# CC430F5123 register map
Registers are 16-bit, read-write, reset 0x0 unless marked. A register's access mark holds for its fields unless they carry their own. Offsets are from the block's base; [hi:lo] are bit positions; {n}, {i} and the like mark numbered series.

## USCI_B0_SPI_Mode
Base 0x00000000
0x5E0 UCB0CTLW0_SPI — USCI B0 Control Word Register 0
0x5E0 UCB0CTL1_SPI 8-bit — USCI B0 Control Register 1
  [8:7] UCSSEL — USCI 1 Clock Source Select 1
    {v}=USCI 0 Clock Source: {v} (v=0..3)
  [0] UCSWRST — USCI Software Reset
0x5E1 UCB0CTL0_SPI 8-bit — USCI B0 Control Register 0
  [7] UCCKPH — Sync. Mode: Clock Phase
  [6] UCCKPL — Sync. Mode: Clock Polarity
  [5] UCMSB — Sync. Mode: MSB first 0:LSB / 1:MSB
  [4] UC7BIT — Sync. Mode: Data Bits 0:8-bits / 1:7-bits
  [3] UCMST — Sync. Mode: Master Select
  [3:2] UCMODE — Sync. Mode: USCI Mode 1
    {v}=Sync. Mode: USCI Mode: {v} (v=0..3)
  [0] UCSYNC — Sync-Mode 0:UART-Mode / 1:SPI-Mode
0x5E6 UCB0BRW_SPI — USCI B0 Baud Word Rate 0
0x5E6 UCB0BR0_SPI 8-bit — USCI B0 Baud Rate 0
0x5E7 UCB0BR1_SPI 8-bit — USCI B0 Baud Rate 1
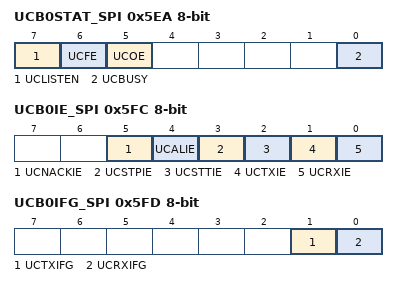
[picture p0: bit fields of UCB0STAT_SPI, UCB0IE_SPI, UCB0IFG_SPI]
0x5EA UCB0STAT_SPI 8-bit — USCI B0 Status Register
  [7] UCLISTEN — USCI Listen mode
  [6] UCFE — USCI Frame Error Flag
  [5] UCOE — USCI Overrun Error Flag
  [0] UCBUSY — USCI Busy Flag
0x5EC UCB0RXBUF_SPI 8-bit — USCI B0 Receive Buffer
0x5EE UCB0TXBUF_SPI 8-bit — USCI B0 Transmit Buffer
0x5FC UCB0ICTL_SPI — USCI B0 Interrupt Enable Register
0x5FC UCB0IE_SPI 8-bit — USCI B0 Interrupt Enable Register
  [5] UCNACKIE — NACK Condition interrupt enable
  [4] UCALIE — Arbitration Lost interrupt enable
  [3] UCSTPIE — STOP Condition interrupt enable
  [2] UCSTTIE — START Condition interrupt enable
  [1] UCTXIE — USCI Transmit Interrupt Enable
  [0] UCRXIE — USCI Receive Interrupt Enable
0x5FD UCB0IFG_SPI 8-bit — USCI B0 Interrupt Flags Register
  [1] UCTXIFG — USCI Transmit Interrupt Flag
  [0] UCRXIFG — USCI Receive Interrupt Flag
0x5FE UCB0IV_SPI — USCI B0 Interrupt Vector Register

## USCI_B0_I2C_Mode
Base 0x00000000
0x5E0 UCB0CTLW0 — USCI B0 Control Word Register 0
0x5E0 UCB0CTL1 8-bit — USCI B0 Control Register 1
  [8:7] UCSSEL — USCI 1 Clock Source Select 1
    {v}=USCI 0 Clock Source: {v} (v=0..3)
  [4] UCTR — Transmit/Receive Select/Flag
  [3] UCTXNACK — Transmit NACK
  [2] UCTXSTP — Transmit STOP
  [1] UCTXSTT — Transmit START
  [0] UCSWRST — USCI Software Reset
0x5E1 UCB0CTL0 8-bit — USCI B0 Control Register 0
  [7] UCA10 — 10-bit Address Mode
  [6] UCSLA10 — 10-bit Slave Address Mode
  [5] UCMM — Multi-Master Environment
  [3] UCMST — Sync. Mode: Master Select
  [3:2] UCMODE — Sync. Mode: USCI Mode 1
    {v}=Sync. Mode: USCI Mode: {v} (v=0..3)
  [0] UCSYNC — Sync-Mode 0:UART-Mode / 1:SPI-Mode
0x5E6 UCB0BRW — USCI B0 Baud Word Rate 0
0x5E6 UCB0BR0 8-bit — USCI B0 Baud Rate 0
0x5E7 UCB0BR1 8-bit — USCI B0 Baud Rate 1
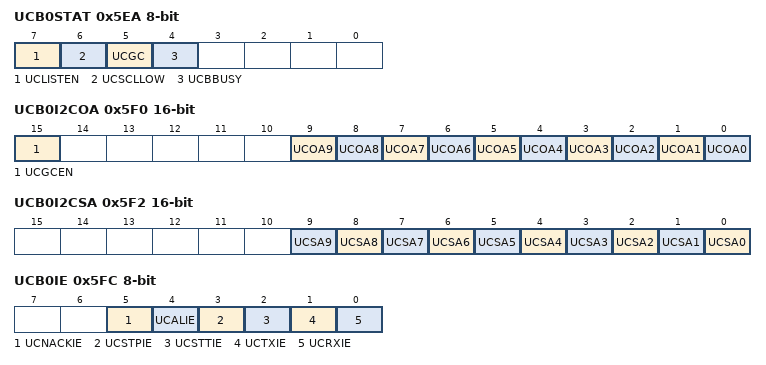
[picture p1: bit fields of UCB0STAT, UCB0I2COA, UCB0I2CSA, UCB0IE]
0x5EA UCB0STAT 8-bit — USCI B0 Status Register
  [7] UCLISTEN — USCI Listen mode
  [6] UCSCLLOW — SCL low
  [5] UCGC — General Call address received Flag
  [4] UCBBUSY — Bus Busy Flag
0x5EC UCB0RXBUF 8-bit — USCI B0 Receive Buffer
0x5EE UCB0TXBUF 8-bit — USCI B0 Transmit Buffer
0x5F0 UCB0I2COA — USCI B0 I2C Own Address
  [15] UCGCEN — I2C General Call enable
  [n] UCOA{n} (n=0..9) — I2C Own Address {n}
0x5F2 UCB0I2CSA — USCI B0 I2C Slave Address
  [n] UCSA{n} (n=0..9) — I2C Slave Address {n}
0x5FC UCB0ICTL — USCI B0 Interrupt Enable Register
0x5FC UCB0IE 8-bit — USCI B0 Interrupt Enable Register
  [5] UCNACKIE — NACK Condition interrupt enable
  [4] UCALIE — Arbitration Lost interrupt enable
  [3] UCSTPIE — STOP Condition interrupt enable
  [2] UCSTTIE — START Condition interrupt enable
  [1] UCTXIE — USCI Transmit Interrupt Enable
  [0] UCRXIE — USCI Receive Interrupt Enable
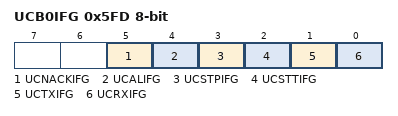
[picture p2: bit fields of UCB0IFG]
0x5FD UCB0IFG 8-bit — USCI B0 Interrupt Flags Register
  [5] UCNACKIFG — NAK Condition interrupt Flag
  [4] UCALIFG — Arbitration Lost interrupt Flag
  [3] UCSTPIFG — STOP Condition interrupt Flag
  [2] UCSTTIFG — START Condition interrupt Flag
  [1] UCTXIFG — USCI Transmit Interrupt Flag
  [0] UCRXIFG — USCI Receive Interrupt Flag
0x5FE UCB0IV — USCI B0 Interrupt Vector Register

## Watchdog_Timer
Base 0x00000000
0x15C WDTCTL — Watchdog Timer Control
  [7] WDTHOLD — WDT - Timer hold
  [7:6] WDTSSEL — WDT - Timer Clock Source Select 0
    0=WDT - Timer Clock Source Select: SMCLK; 1=WDT - Timer Clock Source Select: ACLK; 2=WDT - Timer Clock Source Select: VLO_CLK; 3=WDT - Timer Clock Source Select: reserved
  [4] WDTTMSEL — WDT - Timer Mode Select
  [3] WDTCNTCL — WDT - Timer Clear
  [4:2] WDTIS — WDT - Timer Interval Select 0
    0=WDT - Timer Interval Select: /2G; 1=WDT - Timer Interval Select: /128M; 2=WDT - Timer Interval Select: /8192k; 3=WDT - Timer Interval Select: /512k; 4=WDT - Timer Interval Select: /32k; 5=WDT - Timer Interval Select: /8192; 6=WDT - Timer Interval Select: /512; 7=WDT - Timer Interval Select: /64
